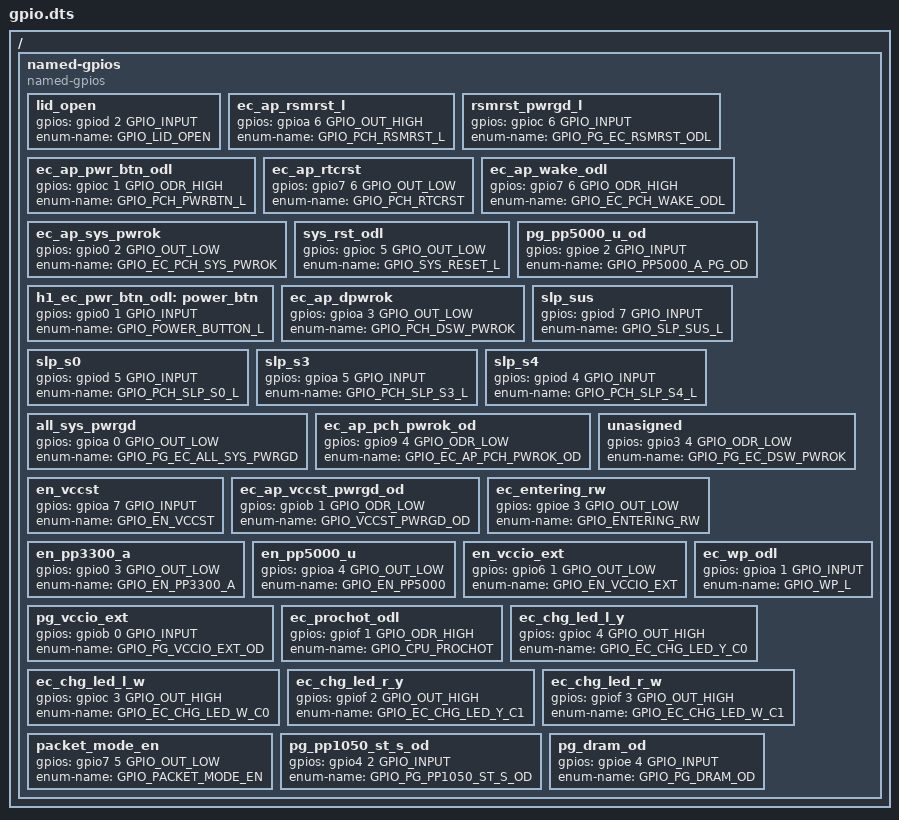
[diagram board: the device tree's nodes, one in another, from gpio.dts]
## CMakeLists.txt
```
# Copyright 2021 The Chromium OS Authors. All rights reserved.
# Use of this source code is governed by a BSD-style license that can be
# found in the LICENSE file.

cmake_minimum_required(VERSION 3.13.1)

find_package(Zephyr REQUIRED HINTS $ENV{ZEPHYR_BASE})
project(madoo)

zephyr_include_directories(include)

zephyr_library_sources_ifdef(CONFIG_PLATFORM_EC_POWERSEQ
  "src/power_signals.c")
```

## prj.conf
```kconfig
# Copyright 2021 The Chromium OS Authors. All rights reserved.
# Use of this source code is governed by a BSD-style license that can be
# found in the LICENSE file.

CONFIG_CROS_EC=y
CONFIG_PLATFORM_EC=y
CONFIG_PLATFORM_EC_BRINGUP=y
CONFIG_SHIMMED_TASKS=y
CONFIG_PLATFORM_EC_POWER_BUTTON=y
CONFIG_PLATFORM_EC_LID_SWITCH=y
CONFIG_PLATFORM_EC_SWITCH=y
CONFIG_LTO=y
CONFIG_CROS_FLASH_NPCX=y
CONFIG_CROS_SYSTEM_NPCX=y
CONFIG_SYSCON=y
CONFIG_AP_X86_INTEL_JSL=y
CONFIG_PLATFORM_EC_POWERSEQ_INTEL=y
CONFIG_PLATFORM_EC_POWERSEQ=y
CONFIG_PLATFORM_EC_POWERSEQ_PP5000_CONTROL=y

#CONFIG_PLATFORM_EC_WATCHDOG=n
CONFIG_CROS_KB_RAW_NPCX=n
CONFIG_PLATFORM_EC_ADC=y
CONFIG_ADC_CMP_NPCX=y
CONFIG_PLATFORM_EC_BACKLIGHT_LID=n
CONFIG_PLATFORM_EC_CONSOLE_CMD_SYSINFO=n
CONFIG_PLATFORM_EC_HOSTCMD=y
CONFIG_PLATFORM_EC_I2C=n
CONFIG_PLATFORM_EC_KEYBOARD=n
CONFIG_PLATFORM_EC_VBOOT_HASH=y
CONFIG_PLATFORM_EC_VBOOT_EFS2=y
CONFIG_PLATFORM_EC_HOST_INTERFACE_ESPI=y
CONFIG_ESPI=y
#PLATFORM_EC_HOST_INTERFACE_HECI=y
CONFIG_LOG=y
```

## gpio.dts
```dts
/* Copyright 2021 The Chromium OS Authors. All rights reserved.
 * Use of this source code is governed by a BSD-style license that can be
 * found in the LICENSE file.
 */

/ {
	named-gpios {
		compatible = "named-gpios";

		lid_open: lid_open {
			gpios = <&gpiod 2 GPIO_INPUT>;
			enum-name = "GPIO_LID_OPEN";
			//label = "LID_OPEN";
		};
		ec_ap_rsmrst_l {
			gpios = <&gpioa 6 GPIO_OUT_HIGH>;
			enum-name = "GPIO_PCH_RSMRST_L";
			//label = "EC_AP_RSMRST_L";
		};
		rsmrst_pwrgd_l {
			gpios = <&gpioc 6 GPIO_INPUT>;
			enum-name = "GPIO_PG_EC_RSMRST_ODL";
			//label = "RSMRST_PWRGD_L";
		};
		ec_ap_pwr_btn_odl {
			gpios = <&gpioc 1 GPIO_ODR_HIGH>;
			enum-name = "GPIO_PCH_PWRBTN_L";
			//label = "EC_AP_PWR_BTN_ODL";
		};
		ec_ap_rtcrst {
			gpios = <&gpio7 6 GPIO_OUT_LOW>;
			enum-name = "GPIO_PCH_RTCRST";
			//label = "EC_PCH_RTCRST";
		};
		ec_ap_wake_odl {
			gpios = <&gpio7 6 GPIO_ODR_HIGH>;
			enum-name = "GPIO_EC_PCH_WAKE_ODL";
			//label = "EC_AP_WAKE_ODL";
		};
		ec_ap_sys_pwrok {
			gpios = <&gpio0 2 GPIO_OUT_LOW>;
			enum-name = "GPIO_EC_PCH_SYS_PWROK";
			//label = "EC_AP_SYS_PWROK";
		};
		sys_rst_odl {
			gpios = <&gpioc 5 GPIO_OUT_LOW>;
			enum-name = "GPIO_SYS_RESET_L";
			//label = "SYS_RST_ODL";
		};
		pg_pp5000_u_od {
			gpios = <&gpioe 2 GPIO_INPUT>;
			enum-name = "GPIO_PP5000_A_PG_OD";
			//label = "PG_PP5000_U_OD";
		};
		h1_ec_pwr_btn_odl: power_btn {
			gpios = <&gpio0 1 GPIO_INPUT>;
			enum-name = "GPIO_POWER_BUTTON_L";
			//label = "H1_EC_PWR_BTN_ODL";
		};
		ec_ap_dpwrok {
			gpios = <&gpioa 3 GPIO_OUT_LOW>;
			enum-name = "GPIO_PCH_DSW_PWROK";
			//label = "EC_AP_DPWROK";
		};
		slp_sus {
			gpios = <&gpiod 7 GPIO_INPUT>;
			enum-name = "GPIO_SLP_SUS_L";
			//label = "SLP_SUS_L";
		};
		slp_s0 {
			gpios = <&gpiod 5 GPIO_INPUT>;
			enum-name = "GPIO_PCH_SLP_S0_L";
			//label = "SLP_S0_L";
		};
		slp_s3 {
			gpios = <&gpioa 5 GPIO_INPUT>;
			enum-name = "GPIO_PCH_SLP_S3_L";
			//label = "SLP_S3_L";
		};
		slp_s4 {
			gpios = <&gpiod 4 GPIO_INPUT>;
			enum-name = "GPIO_PCH_SLP_S4_L";
			//label = "SLP_S4_L";
		};
		all_sys_pwrgd {
			gpios = <&gpioa 0 GPIO_OUT_LOW>;
			enum-name = "GPIO_PG_EC_ALL_SYS_PWRGD";
			//label = "ALL_SYS_PWRGD";
		};
		ec_ap_pch_pwrok_od {
			gpios = <&gpio9 4 GPIO_ODR_LOW>;
			enum-name = "GPIO_EC_AP_PCH_PWROK_OD";
			//label = "GPIO_EC_AP_PCH_PWROK_OD";
		};
		unasigned {
			gpios = <&gpio3 4 GPIO_ODR_LOW>;
			enum-name = "GPIO_PG_EC_DSW_PWROK";
			//label = "GPIO_PG_EC_DSW_PWROK";
		};
		en_vccst {
			gpios = <&gpioa 7 GPIO_INPUT>;
			enum-name = "GPIO_EN_VCCST";
			//label = "EN_VCCST";
		};
		ec_ap_vccst_pwrgd_od {
			gpios = <&gpiob 1 GPIO_ODR_LOW>;
			enum-name = "GPIO_VCCST_PWRGD_OD";
			//label = "EC_AP_VCCST_PWRGD_OD";
		};
		ec_entering_rw {
			gpios = <&gpioe 3 GPIO_OUT_LOW>;
			enum-name = "GPIO_ENTERING_RW";
			//label = "EC_ENTERING_RW";
		};
		en_pp3300_a {
			gpios = <&gpio0 3 GPIO_OUT_LOW>;
			enum-name = "GPIO_EN_PP3300_A";
			//label = "EN_PP3300_A";
		};
		en_pp5000_u {
			gpios = <&gpioa 4 GPIO_OUT_LOW>;
			enum-name = "GPIO_EN_PP5000";
			//label = "EN_PP5000_U";
		};
		en_vccio_ext {
			gpios = <&gpio6 1 GPIO_OUT_LOW>;
			enum-name = "GPIO_EN_VCCIO_EXT";
			//label = "EN_VCCIO_EXT";
		};
		pg_vccio_ext {
			gpios = <&gpiob 0 GPIO_INPUT>;
			enum-name = "GPIO_PG_VCCIO_EXT_OD";
			//label = "GPIO_PG_VCCIO_EXT_OD";
		};
		ec_prochot_odl {
			gpios = <&gpiof 1 GPIO_ODR_HIGH>;
			enum-name = "GPIO_CPU_PROCHOT";
			//label = "EC_PROCHOT_ODL";
		};
		ec_wp_odl {
			gpios = <&gpioa 1 GPIO_INPUT>;
			enum-name = "GPIO_WP_L";
			//label = "EC_WP_ODL";
		};
		ec_chg_led_l_y {
			gpios = <&gpioc 4 GPIO_OUT_HIGH>;
			enum-name = "GPIO_EC_CHG_LED_Y_C0";
			//label = "EC_CHG_LED_L_Y";
		};
		ec_chg_led_l_w {
			gpios = <&gpioc 3 GPIO_OUT_HIGH>;
			enum-name = "GPIO_EC_CHG_LED_W_C0";
			//label = "EC_CHG_LED_L_W";
		};
		ec_chg_led_r_y {
			gpios = <&gpiof 2 GPIO_OUT_HIGH>;
			enum-name = "GPIO_EC_CHG_LED_Y_C1";
			//label = "EC_CHG_LED_R_Y";
		};
		ec_chg_led_r_w {
			gpios = <&gpiof 3 GPIO_OUT_HIGH>;
			enum-name = "GPIO_EC_CHG_LED_W_C1";
			//label = "EC_CHG_LED_R_W";
		};
		packet_mode_en {
			gpios = <&gpio7 5 GPIO_OUT_LOW>;
			enum-name = "GPIO_PACKET_MODE_EN";
			//label = "EC_GSC_PACKET_MODE";
		};
		pg_pp1050_st_s_od {
			gpios = <&gpio4 2 GPIO_INPUT>;
			enum-name = "GPIO_PG_PP1050_ST_S_OD";
			//label = "GPIO_PG_PP1050_ST_S_OD";
		};
		pg_dram_od {
			gpios = <&gpioe 4 GPIO_INPUT>;
			enum-name = "GPIO_PG_DRAM_OD";
			//label = "GPIO_PG_DRAM_O";
		};
	};
};
```

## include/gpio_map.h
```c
/* Copyright 2021 The Chromium OS Authors. All rights reserved.
 * Use of this source code is governed by a BSD-style license that can be
 * found in the LICENSE file.
 */

#ifndef __ZEPHYR_GPIO_MAP_H
#define __ZEPHYR_GPIO_MAP_H

#include <devicetree.h>
#include <gpio_signal.h>

#define POWER_SIGNAL_INT(gpio, edge)                                      \
	GPIO_INT(gpio, edge, power_signal_interrupt)
/*
 * Set EC_CROS_GPIO_INTERRUPTS to a space-separated list of GPIO_INT items.
 *
 * Each GPIO_INT requires three parameters:
 *   gpio_signal - The enum gpio_signal for the interrupt gpio
 *   interrupt_flags - The interrupt-related flags (e.g. GPIO_INT_EDGE_BOTH)
 *   handler - The platform/ec interrupt handler.
 *
 * Ensure that this files includes all necessary headers to declare all
 * referenced handler functions.
 *
 * For example, one could use the follow definition:
 * #define EC_CROS_GPIO_INTERRUPTS \
 *   GPIO_INT(NAMED_GPIO(h1_ec_pwr_btn_odl), GPIO_INT_EDGE_BOTH, button_print)
 */

#define EC_CROS_GPIO_INTERRUPTS                                           \
	POWER_SIGNAL_INT(GPIO_PCH_SLP_S0_L, GPIO_INT_EDGE_BOTH)           \
	GPIO_INT(GPIO_PCH_SLP_S3_L, GPIO_INT_EDGE_BOTH,                   \
		baseboard_all_sys_pgood_interrupt)                        \
	POWER_SIGNAL_INT(GPIO_PCH_SLP_S4_L, GPIO_INT_EDGE_BOTH)           \
	POWER_SIGNAL_INT(GPIO_SLP_SUS_L, GPIO_INT_EDGE_BOTH)              \
	POWER_SIGNAL_INT(GPIO_PG_EC_RSMRST_ODL, GPIO_INT_EDGE_BOTH)       \
	GPIO_INT(GPIO_PG_VCCIO_EXT_OD, GPIO_INT_EDGE_BOTH,                \
		baseboard_all_sys_pgood_interrupt)                        \
	GPIO_INT(GPIO_LID_OPEN, GPIO_INT_EDGE_BOTH, lid_interrupt)        \
	POWER_SIGNAL_INT(GPIO_PP5000_A_PG_OD, GPIO_INT_EDGE_BOTH)         \
	GPIO_INT(GPIO_PG_DRAM_OD, GPIO_INT_EDGE_BOTH,                     \
		baseboard_all_sys_pgood_interrupt)                        \
	POWER_SIGNAL_INT(GPIO_PG_PP1050_ST_S_OD, GPIO_INT_EDGE_BOTH)      \
	GPIO_INT(GPIO_POWER_BUTTON_L, GPIO_INT_EDGE_BOTH,                 \
		power_button_interrupt)                                   \
	GPIO_INT(GPIO_WP_L, GPIO_INT_EDGE_BOTH, switch_interrupt)
#endif /* __ZEPHYR_GPIO_MAP_H */
```

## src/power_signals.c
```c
/* Copyright 2021 The Chromium OS Authors. All rights reserved.
 * Use of this source code is governed by a BSD-style license that can be
 * found in the LICENSE file.
 */

#include "gpio.h"
#include "hooks.h"
#include "adc.h"
#include "drivers/sensor.h"
#include "power.h"
#include "power/icelake.h"
#include "power/intel_x86.h"

#define CPRINTS(format, args...) cprints(CC_CHIPSET, format, ## args)

#define pp3300_on_dev DEVICE_DT_GET(DT_NODELABEL(cmp_pp3300_high))
#define pp3300_off_dev DEVICE_DT_GET(DT_NODELABEL(cmp_pp3300_low))

atomic_t pp3300_a_pgood = 0;

const struct intel_x86_pwrok_signal pwrok_signal_assert_list[] = {
	{
		.gpio = GPIO_PG_EC_ALL_SYS_PWRGD,
	},
	{
		.gpio = GPIO_VCCST_PWRGD_OD,
		.delay_ms = 2,
	},
	{
		.gpio = GPIO_EC_AP_PCH_PWROK_OD,
	},
	{
		.gpio = GPIO_EC_PCH_SYS_PWROK,
	},
};
const int pwrok_signal_assert_count = ARRAY_SIZE(pwrok_signal_assert_list);

const struct intel_x86_pwrok_signal pwrok_signal_deassert_list[] = {
	/* No delays needed during S0 exit */
	{
		.gpio = GPIO_VCCST_PWRGD_OD,
	},
	{
		.gpio = GPIO_EC_AP_PCH_PWROK_OD,
	},
	{
		.gpio = GPIO_EC_PCH_SYS_PWROK,
	},
	/* Turn off the VCCIN rail last */
	{
		.gpio = GPIO_PG_EC_ALL_SYS_PWRGD,
	},
};
const int pwrok_signal_deassert_count = ARRAY_SIZE(pwrok_signal_deassert_list);

__override void board_after_rsmrst(int rsmrst)
{
	/*
	 * b:148688874: If RSMRST# is de-asserted, enable the pull-up on
	 * PG_PP1050_ST_OD.  It won't be enabled prior to this signal going high
	 * because the load switch for PP1050_ST cannot pull the PG low.  Once
	 * it's asserted, disable the pull up so we don't inidicate that the
	 * power is good before the rail is actually ready.
	 */
	int flags = rsmrst ? GPIO_PULL_UP : 0;

	flags |= GPIO_INT_BOTH;

	gpio_set_flags(GPIO_PG_PP1050_ST_S_OD, flags);
}

/* Store away PP300_A good status before sysjumps */
#define BASEBOARD_SYSJUMP_TAG   0x4242 /* BB */
#define BASEBOARD_HOOK_VERSION  1

static void pp3300_a_pgood_preserve(void)
{
	system_add_jump_tag(BASEBOARD_SYSJUMP_TAG, BASEBOARD_HOOK_VERSION,
			    sizeof(pp3300_a_pgood), &pp3300_a_pgood);
}
DECLARE_HOOK(HOOK_SYSJUMP, pp3300_a_pgood_preserve, HOOK_PRIO_DEFAULT);

static void baseboard_prepare_power_signals(void)
{
	const int *stored;
	int version, size;

	stored = (const int *)system_get_jump_tag(BASEBOARD_SYSJUMP_TAG,
						  &version, &size);
	if (stored && (version == BASEBOARD_HOOK_VERSION) &&
	   (size == sizeof(pp3300_a_pgood)))
		/* Valid PP3300 status found, restore before CHIPSET init */
		pp3300_a_pgood = *stored;

	/* Restore pull-up on PG_PP1050_ST_OD */
	if (system_jumped_to_this_image() &&
	    gpio_get_level(GPIO_PG_EC_RSMRST_ODL))
		board_after_rsmrst(1);
}
DECLARE_HOOK(HOOK_INIT, baseboard_prepare_power_signals, HOOK_PRIO_FIRST);

int extpower_is_present(void)
{
	/* Empty function to satisfy compiler and avoid build failure */
	return 0;
}

__override int intel_x86_get_pg_ec_dsw_pwrok(void)
{
	/*
	 * The PP3300_A rail is an input to generate DPWROK.  Assuming that
	 * power is good if voltage is at least 80% of nominal level.  We cannot
	 * read the ADC values during an interrupt, therefore, this power good
	 * value is updated via ADC threshold interrupts.
	 */
	return pp3300_a_pgood;
}

__override int power_signal_get_level(enum gpio_signal signal)
{
	if (signal == GPIO_PG_EC_DSW_PWROK)
		return intel_x86_get_pg_ec_dsw_pwrok();

	if (signal == GPIO_PG_EC_ALL_SYS_PWRGD)
		return intel_x86_get_pg_ec_all_sys_pwrgd();

	if (IS_ENABLED(CONFIG_HOSTCMD_ESPI)) {
		/* Check signal is from GPIOs or VWs */
		if (espi_signal_is_vw(signal))
			return espi_vw_get_wire(signal);
	}
	return gpio_get_level(signal);
}

void baseboard_all_sys_pgood_interrupt(enum gpio_signal signal)
{
	/*
	 * We need to deassert ALL_SYS_PGOOD within 200us of SLP_S3_L asserting.
	 * that is why we do this here instead of waiting for the chipset
	 * driver to.
	 * Early protos do not pull VCCST_PWRGD below Vil in hardware logic,
	 * so we need to do the same for this signal.
	 * Pull EN_VCCIO_EXT to LOW, which ensures VCCST_PWRGD remains LOW during
	 * SLP_S3_L assertion.
	 */
	if (!gpio_get_level(GPIO_PCH_SLP_S3_L)) {
		gpio_set_level(GPIO_PG_EC_ALL_SYS_PWRGD, 0);
		gpio_set_level(GPIO_EN_VCCIO_EXT, 0);
		gpio_set_level(GPIO_VCCST_PWRGD_OD, 0);
		gpio_set_level(GPIO_EC_AP_PCH_PWROK_OD, 0);
	}
	/* Now chain off to the normal power signal interrupt handler. */
	power_signal_interrupt(signal);
}

__override int intel_x86_get_pg_ec_all_sys_pwrgd(void)
{
	/*
	 * SLP_S3_L is a qualifying input signal to ALL_SYS_PWRGD logic.
	 * So ensure ALL_SYS_PWRGD remains LOW during SLP_S3_L assertion.
	 */
	if (!gpio_get_level(GPIO_PCH_SLP_S3_L))
		return 0;
	/*
	 * ALL_SYS_PWRGD is an AND of DRAM PGOOD, VCCST PGOOD, and VCCIO_EXT
	 * PGOOD.
	 */
	return gpio_get_level(GPIO_PG_PP1050_ST_S_OD) &&
		gpio_get_level(GPIO_PG_DRAM_OD) &&
		gpio_get_level(GPIO_PG_VCCIO_EXT_OD);
}

static void pp3300_a_pgood_cb(const struct device *dev, const struct sensor_trigger *trigger)
{
	struct sensor_value val;

	if (dev == pp3300_on_dev) {
		atomic_or(&pp3300_a_pgood, 1);

		/* Disable this interrupt while it's asserted. */
		val.val1 = false;
		sensor_attr_set(pp3300_on_dev, SENSOR_CHAN_VOLTAGE,
			SENSOR_ATTR_ALERT, &val);

		/* Enable the voltage low interrupt. */
		val.val1 = true;
		sensor_attr_set(pp3300_off_dev, SENSOR_CHAN_VOLTAGE,
			SENSOR_ATTR_ALERT, &val);
	}
	else if (dev == pp3300_off_dev) {
		atomic_clear_bits(&pp3300_a_pgood, 1);

		/* Disable this interrupt while it's asserted. */
		val.val1 = false;
		sensor_attr_set(pp3300_off_dev, SENSOR_CHAN_VOLTAGE,
			SENSOR_ATTR_ALERT, &val);

		/* Enable the voltage high interrupt. */
		val.val1 = true;
		sensor_attr_set(pp3300_on_dev, SENSOR_CHAN_VOLTAGE,
			SENSOR_ATTR_ALERT, &val);
	}
	/*
	 * Call power_signal_interrupt() with a fake GPIO in order for the
	 * chipset task to pick up the change in power sequencing signals.
	 */
	power_signal_interrupt(GPIO_PG_EC_DSW_PWROK);
}

static int baseboard_init(const struct device *device)
{

	struct sensor_value val;
	struct sensor_trigger trig = {
		.type = SENSOR_TRIG_THRESHOLD,
		.chan = SENSOR_CHAN_VOLTAGE
	};

	sensor_trigger_set(pp3300_on_dev, &trig, pp3300_a_pgood_cb);
	val.val1 = true;
	sensor_attr_set(pp3300_on_dev, SENSOR_CHAN_VOLTAGE,
		SENSOR_ATTR_ALERT, &val);
	sensor_trigger_set(pp3300_off_dev, &trig, pp3300_a_pgood_cb);

	return 0;
}
SYS_INIT(baseboard_init, POST_KERNEL, 55);
```
